# MSS_CPSW register map
Vendor: Texas Instruments
Peripheral module from a debugger description file (folder awr2544).
Registers are 32-bit, read-write, no defined reset value unless marked. A register's access mark holds for its fields unless they carry their own. Offsets are as the file gives them; lines under a group give offsets from that group; [hi:lo] are bit positions; {n}, {i} and the like mark numbered series; 'fields as' and 'values as' point back to an identical list; <NAME> marks a mode.

## MSS_CPSW (part 1 of 3)
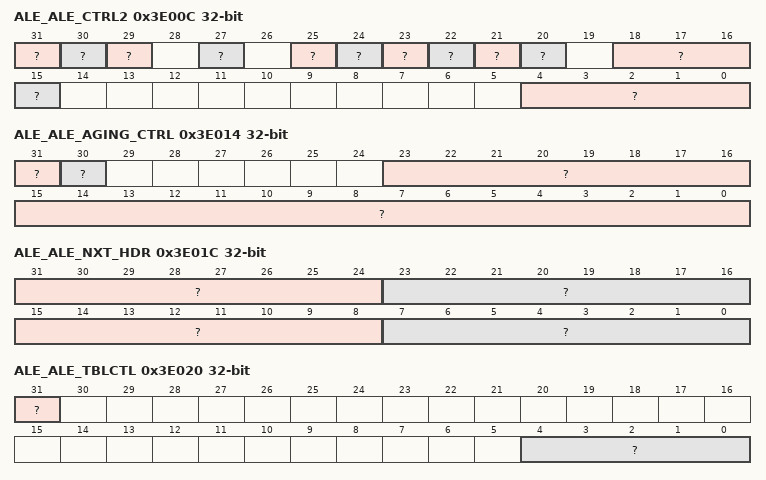
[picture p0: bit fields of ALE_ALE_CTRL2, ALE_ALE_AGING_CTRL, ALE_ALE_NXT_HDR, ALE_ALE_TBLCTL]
0x3E00C ALE_ALE_CTRL2 — The ALE Control 2 Register is used to set the extended features used for all ports.
  [31] ? — Trunk Enable Destination Address - This field enables the destination MAC address to be used with the hash function G(X) = 1 + X + X^3 and affect the trunk port transmit link determination.
  [30] ? — Trunk Enable Source Address - This field enables the source MAC address to be used with the hash function G(X) = 1 + X + X^3 and affect the trunk port transmit link determination.
  [29] ? — Trunk Enable Priority - This field enables the VLAN Priority bits to be used with the hash function G(X) = 1 + X + X^3 and affect the trunk port transmit link determination. In the event that DSCP mapping is enabled and there is no VLAN the DSCP priority will be used. For all other non IP frames without VLAN the port default priority is used.
  [27] ? — Trunk Enable Inner VLAN - This field enables the inner VLAN ID value (C-VLANID) to be used with the hash function G(X) = 1 + X + X^3 and affect the trunk port transmit link determination.
  [25] ? — Trunk Enable Source IP Address - This field enables the source IP address to be used with the hash function G(X) = 1 + X + X^3 and affect the trunk port transmit link determination.#br#This feature supports No tag, Priority tagged, VLAN tagged, Q-in-Q double tagging for both IPV6 and IPV4.
  [24] ? — Trunk Enable Destination IP Address - This field enables the destination IP address to be used with the hash function G(X) = 1 + X + X^3 and affect the trunk port transmit link determination.#br#This feature supports No tag, Priority tagged, VLAN tagged, Q-in-Q double tagging for both IPV6 and IPV4.
  [23] ? — Drop Bad Length will drop any packet that the 802.3 length field is larger than the packet. Ethertypes 0-1500 are 802.3 lengths, all others are Ether types.
  [22] ? — No Drop Source Multicast will disable the dropping of any source address with the multicast bit set.
  [21] ? — Default No Frag field will cause an IPv4 fragmented packet to be dropped if a VLAN entry is not found.
  [20] ? — Default limit next header field will cause an IPv4 protocol or IPv6 next header packet to be dropped if a VLAN entry is not found and the protocol or next header does not match the ~iALE_NXT_HDR register values.
  [18:16] ? — Trunk Base - This field is the hash formula starting value. Changing this value will cause the packet distribution on trunk ports to be changed. If all the ~itrk_en_dst, ~itrk_en_src, ~itrk_en_pri and ~itrk_en_vlan are '0', this value is used as the distribution index. That is a '0' will select the 1st bit of an 'N' link trunk, a '1' will select the second, etc. #br#Below is the distribution across the trunk links. The first number in the ~iitalic sequence indicates the traffic is sent to the lowest numbered port of a trunk group. For example if you have a 3 port trunk, the hash result 0 will go to the base port (0), hash result 1 will go to the highest port of the trunk group (2), hash result 2 will go to the middle port (1), etc.#br# 1 - ~i00000000#br# 2 - ~i01010101#br# 3 - ~i02102102#br# 4 - ~i03210321
  [15] ? — The ~multihost allows host traffic to be sent bact to the host if the DA is market for the host port.
  [4:0] ? — Mirror Index - This field is the ALE lookup table entry index that when a match occurs will cause this traffic to be mirrored to the ~imirror_top port. That is any VLAN, ONU or address with or withou VLAN can be selected for traffic mirroring.
0x3E010 ALE_ALE_PRESCALE — The ALE Prescale Register is used to set the Broadcast and Multicast rate limiting prescaler value.
  [19:0] ? — ALE Prescale - The input clock is divided by this value for use in the multicast/broadcast rate limiters. The minimum operating value is 0x10. The prescaler is off when the value is zero.
0x3E014 ALE_ALE_AGING_CTRL — The ALE Aging Control sets the aging interval which will cause periodic aging to occur. This value specifies the minimum time between aging starts.
  [31] ? — ALE Prescaler 2 Disable - When set will divide the aging interval by 1000. This bit is designed for device verification and should not be used in production software. Combination of PreScale1Disable and PreScale2Disable will divide the aging interval by 1,000,000 for test purposes.
  [30] ? — ALE Prescaler 1 Disable - When set will divide the aging interval by 1000. This bit is designed for device verification and should not be used in production software. Combination of PreScale1Disable and PreScale2Disable will divide the aging interval by 1,000,000 for test purposes.
  [23:0] ? — ALE Aging Timer - This field specifies the number of clock cycles times 1,000,000 between aging operations.
0x3E01C ALE_ALE_NXT_HDR — The ALE Next Header is used to limit the IPv6 Next header or IPv4 Protocol values found in the IP header. It is enabled via the ~iLmtNxtHdr bit in the VLAN entry. All four ~iip_nxt_hdr0-3 are compared when enabled, so if only one is required, set them all to the one value to be tested.
  [31:24] ? — The ~iip_nxt_hdr3 is the forth protocol or next header compared when enabled.
  [23:16] ? — The ~iip_nxt_hdr2 is the third protocol or next header compared when enabled.
  [15:8] ? — The ~iip_nxt_hdr1 is the second protocol or next header compared when enabled.
  [7:0] ? — The ~iip_nxt_hdr0 is the first protocol or next header compared when enabled.
0x3E020 ALE_ALE_TBLCTL — The ALE table control register is used to read or write that ALE table entries. After writing to this register any read or write to any ALE register will be stalled until the read or write operation completes.
  [31] ? — Table Write - This bit is used to write the table words to the lookup table.#br# 0 - Table Read Operation is performed. The contents of the ~b TABLEIDX entry will be read into the ~b ALE_TBLWx registers#br# 1 - Table write operation is performed. This will take the current contents from the ~b ALE_TBLWx registers and write them to the table at the specified ~b TABLEIDX.
  [4:0] ? — The table index is used to determine which lookup table entry is read or written.
0x3E034 ALE_ALE_TBLW2 — The ALE Table Word 2 is the most significant word of an ALE table entry.
  [6:0] ? — Table Entry bits [71:64]
0x3E038 ALE_ALE_TBLW1 — The ALE Table Word 1 is the middle word of an ALE table entry.
  [31:0] ? — Table Entry bits [63:32]
0x3E03C ALE_ALE_TBLW0 — The ALE Table Word 0 is the least significant word of an ALE table entry.
  [31:0] ? — Table Entry bits [31:0]
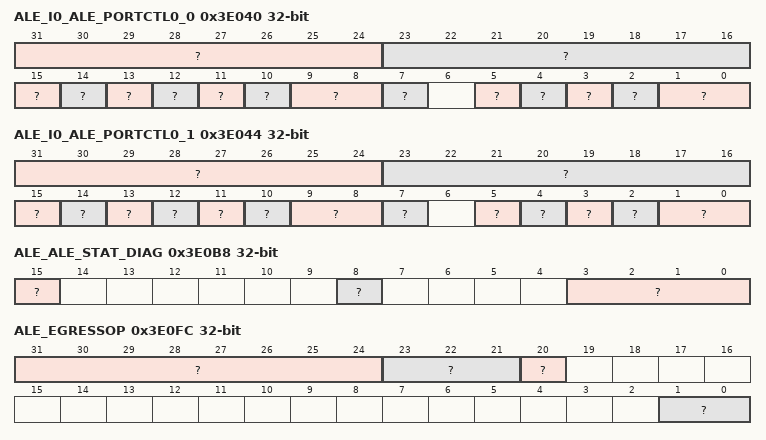
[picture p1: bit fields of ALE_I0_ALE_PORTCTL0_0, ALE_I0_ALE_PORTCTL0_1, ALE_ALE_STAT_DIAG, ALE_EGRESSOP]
0x3E040 ALE_I0_ALE_PORTCTL0_0 — The ALE Port Control Register sets the port specific modes of operation.
  [31:24] ? — Broadcast Packet Rate Limit - Each prescale pulse loads this field into the port broadcast rate limit counter. The port counters are decremented with each packet received or transmitted depending on whether the mode is transmit or receive. If the counters decrement to zero, then further packets are rate limited until the next prescale pulse.#br#Broadcast rate limiting is enabled by a non-zero value in this field.
  [23:16] ? — Multicast Packet Rate Limit - Each prescale pulse loads this field into the port multicast rate limit counter. The port counters are decremented with each packet received or transmitted depending on whether the mode is transmit or receive. If the counters decrement to zero, then further packets are rate limited until the next prescale pulse.#br#Multicast rate limiting is enabled by a non-zero value in this field.The ~imcast_limit is the number of Multicast packets that will be forwaded per ~iale_prescale time.
  [15] ? — Drop Double VLAN - When set cause any received packet with double VLANs to be dropped. That is if there are two ctag or two stag fields in the packet it will be dropped.
  [14] ? — Drop Dual VLAN - When set will cause any received packet with dual VLAN stag followed by ctag to be dropped.
  [13] ? — Mac Only Copy All Frames - When set a Mac Only port will transfer all received good frames to the host. When clear a Mac Only port will transfer packets to the host based on ALE destination address lookup operation (which operates more like an Ethernet Mac).#br#A Mac Only port is a port with ~imaconly set.
  [12] ? — Disable Port authorization - When set will allow unknown addresses to arrive on a switch in authorization mode. It is intended for device to device network connection on ports which do not require MACSEC encryption.
  [11] ? — MAC Only - When set enables this port be treated like a MAC port for the host. All traffic received is only sent to the host. The host must direct traffic to this port as the lookup engine will not send traffic to the ports with the ~ip0_maconly bit set and the ~ip0_no_learn also set. If ~ip0_maconly bit is set and the ~ip0_no_learn is not set, the host can send non-directed packets that can be sent to the destination of a MacOnly port. It is also possible that The host can broadcast to all ports including MacOnly ports in this mode.
  [10] ? — Trunk Enable - This field is used to enable a port into a trunk. Any port can be used as a trunk port, any two or more ports with the ~ip0_trunken its set and having the same ~ip0_trunknum will be placed in the same trunk. There is no requirement for trunk ports to be adjacent. If all ports are enabled in the same trunk, no traffic can flow as traffic received within a trunk is never trasnmitted out the same trunk. If only a single port is a member of a trunk, it looks like a normal port with exception of entries in the look up table will be noted as a trunk entry.
  [9:8] ? — Trunk Number - This field is used as the trunk number when the ~ip0_trunken is also set. Ports with the same trunk number that have the ~ip0_trunken also set will have traffic distributed within the trunk based on the result of the hash function descrived above.
  [7] ? — Mirror Source Port - This field enables the source port mirror option. When this bit is set any traffic received on the port with the reg_p0_mirror_sp bit set will have its received traffic also sent to the ~imirror_top port.
  [5] ? — No Source Address Update - When set will not update the source addresses for this port.
  [4] ? — No Learn - When set will not learn the source addresses for this port.
  [3] ? — VLAN Ingress Check - When set if a packet received is not a member of the VLAN, the packet will be dropped.
  [2] ? — If Drop Untagged - When set will drop packets without a VLAN tag.
  [1:0] ? — Port State - Defins the current port state used for lookup operations.#br# 0 - Disabled#br# 1 - Blocked#br# 2 - Learning#br# 3 - Forwarding
0x3E044 ALE_I0_ALE_PORTCTL0_1 — The ALE Port Control Register sets the port specific modes of operation.
  fields as ALE_I0_ALE_PORTCTL0_0
0x3E090 ALE_ALE_UVLAN_MEMBER — The ALE Unknown VLAN Member Mask Register is used to specify the member list for unknown VLAN ID.
  [1:0] ? — Unknown VLAN Member List - Each bit represents the port member status for unknown VLANs.
0x3E094 ALE_ALE_UVLAN_URCAST — The ALE Unknown VLAN Unregistered Multicast Flood Mask Register is used to specify which egress ports unregistered multicast addresses egress for the unregistered VLAN ID.
  [1:0] ? — Unknown VLAN Unregister Multicast Flood Mask - Each bit represents the port to which unregistered multicast are sent for unregistered VLANs.
0x3E098 ALE_ALE_UVLAN_RMCAST — The ALE Unknown VLAN Registered Multicast Flood Mask Register is used to specify which egress ports registered multicast addresses egress for the unregistered VLAN ID.
  [1:0] ? — Unknown VLAN Register Multicast Flood Mask - Each bit represents the port to which registered multicast are sent for unregistered VLANs. This field is ANDed with the registered multicast mask to determine the destinations for unregistered VLANs.
0x3E09C ALE_ALE_UVLAN_UNTAG — The ALE Unknown VLAN force Untagged Egress Mask Register is used to specify which egress ports the VLAN ID will be removed.
  [1:0] ? — Unknown VLAN Force Untagged Egress Mask - Each bit represents the port where the VLAN will be removed for unregistered VLANs.
0x3E0B4 ALE_ALE_FAST_LUT — The Fast LUT registers allows the ports to be placed in Fast LUT mode.
  [1:0] ? — The ~Fast_LUT field alows any port to be Fast_LUT mode, which will cause all lookup operations to start based on DA/SA and VLAN only. That is any data beyong the first 32 are not used in the lookup process.
0x3E0B8 ALE_ALE_STAT_DIAG — The ALE Statistic Output Diagnostic Register allows the output statistics to diagnose the SW counters. This register is for diagnostice only.
  [15] ? — When set and the ~iport_diag is set to zero, will allow all ports to see the same stat diagnostic increment.
  [8] ? — The port selected that a received packet will cause the selected error to increment
  [3:0] ? — When non-zero will cause the selected statistic to increment on the next frame received. For the selected Port. #br# 0: Disabled#br# 1: Destination Equal Source Drop Stat will count#br# 2: VLAN Ingress Check Drop Stat will count#br# 3: Source Multicast Drop Stat will count#br# 4: Dual VLAN Drop Stat will count#br# 5: Ether Type length error Drop Stat will count#br# 6: Next Hop Limit Drop Stat will count#br# 7: IPv4 Fragment Drop Stat will count#br# 8: Classifier Hit Stat will count#br# 9: Classifier Red Drop Stat will count#br# 10: Classifier Yellow Drop Stat will count#br# 11: ALE Overflow Drop Stat will count#br# 12: Rate Limit Drop Stat will count#br# 13: Blocked Address Drop Stat will count#br# 14: Secure Address Drop Stat will count#br# 15: Authorization Drop Stat will count.
0x3E0BC ALE_ALE_OAM_LB_CTRL — The ALE OAM Control allows ports to be put into OAM Loopback, only non-supervisor packet are looped back to the source port.
  [1:0] ? — The ~ioam_lb_ctrl allows any port to be put into OAM loopback, that is any packet received will be returned to the same port with an egressop of 0xFF which swaps the source and destination address. BPDUs will still flow through as normal so that OAM can be remotly requested and disabled.
0x3E0C0 ALE_ALE_MSK_MUX0 ro — VLAN Mask Mux x - The ALE Mask Mux registers are used along with the VLAN registered/unregistered index selectors from the Lookup Table to determine the value for vlan registered and unregister mask respectively.
  [1:0] ? — VLAN Mask Mux x - When selected by the VLAN lookup table entry FwdUnRegIdx or FwdAllRegIdx is used as the FwdUnRegMask or FwdUnRegMask values anded with the member list to determine the forwarding of packets. The Value of vlan_mask_mux_0 is read only and set to all ones for all ports.
{0x3E0C4+4i} ALE_I1_ALE_MSK_MUX1_{i} (i=0..2) — VLAN Mask Mux x - The ALE Mask Mux registers are used along with the VLAN registered/unregistered index selectors from the Lookup Table to determine the value for vlan registered and unregister mask respectively.
  fields as ALE_ALE_MSK_MUX0
0x3E0FC ALE_EGRESSOP — The Egress Operation register allows enabled classifiers with any match like IPSA or IPDA match to use the CPSW Egress Packet Operations Inter VLAN Routing sub functions. If the packet was destined for the host or is destined to any port without any errors, but matches a clasifier that has a programmed egress opcode, it will be forwarded to the destination ports where the destination ports will use the thier egress opcode entry to modify the packet. InterVLAN Routing and mirroring need to be understood, they are orthogonal functions. Care must be taken not to violate VLAN rules as this can redirect packets based on classifier matches.
  [31:24] ? — The Egress Operation defines the operation performed by the CPSW Egress Packet Operations#br# 0: NOP#br#: 1-n: Defines which egress Operation will be performed. This allows Inter VLAN routing to be configured for high bandwidth traffic, reducing CPU load.#br# 0xff: Swap SA and DA of packet, this is intended to allow OAM diagnostics for a link.
  [23:21] ? — The Egress Trunk Index is the calculated trunk index from the SA, DA or VLAN if modified to that InterVLAN routing will work on trunks as well. The DA, SA and VLAN are ignored for trunk generation on InterVLAN Routing so that this field is the index generated from the Egress Op replacements elclusive or'd together into a three bit index.
  [20] ? — The TTL Check will cause any packet that fails TTL checks to not be routed to the Inter VLAN Routing sub functions. The packet will be routed to the host it was destined to.
  [1:0] ? — The Destination Ports is a list of the ports the classified packet will be set to. If a destination is a Trunk, all the port bits for that trunck must be set.
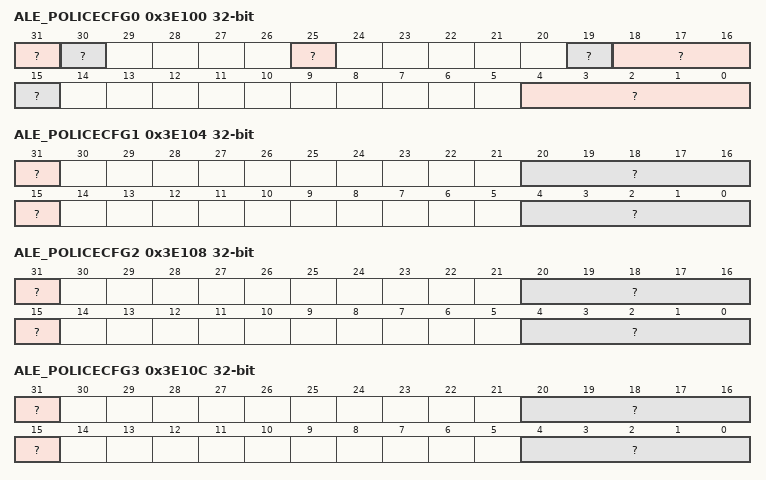
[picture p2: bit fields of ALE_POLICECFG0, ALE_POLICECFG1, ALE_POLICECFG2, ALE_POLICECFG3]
0x3E100 ALE_POLICECFG0 — The Policing Config 0 holds the port, frame priority and ONU address index as well as match enables for port, frame priority and ONU address matching.
  [31] ? — Port Match Enable - Enabled port match for the selected policing/classifier entry
  [30] ? — Trunk ID - When set indicates the port number is a trunk group.
  [25] ? — Port Number - Specifies the port address to match for the selected policing/classifier entry
  [19] ? — Priority Match Enable - Enables frame priority match for the selected policing/classifier entry
  [18:16] ? — Priority Value - Specifies the frame priority to match for the selected policing/classifier entry
  [15] ? — OUI Match Enable - Enables frame ONU address match for the selected policing/classifier entry
  [4:0] ? — OUI Table Entry Index - Specifies the ALE ONU address lookup table index to match for the selected policing/classifier entry
0x3E104 ALE_POLICECFG1 — The Policing Config 1 holds the match enable/match index for the L2 Destination and L2 source addresses
  [31] ? — Destination Address Match Enable - Enables frame L2 destination address match for the selected policing/classifier entry
  [20:16] ? — Destination Address Table Entry Index - Specifies the ALE L2 destination address lookup table index to match for the selected policing/classifier entry
  [15] ? — Source Address Match Enable - Enables frame L2 source address match for the selected policing/classifier entry
  [4:0] ? — Source Address Table Entry Index - Specifies the ALE L2 source address lookup table index to match for the selected policing/classifier entry
0x3E108 ALE_POLICECFG2 — The Policing Config 2 holds the match enable/match index for the Outer VLAN and Inner VLAN addresses
  [31] ? — Outer VLAN Match Enable - Enables frame Outer VLAN address match for the selected policing/classifier entry
  [20:16] ? — Outer VLAN Table Entry Index - Specifies the ALE Outer VLAN address lookup table index to match for the selected policing/classifier entry#br# Note this index assumes the VLANID is in the packet, it does not use the port VLAN if the packet in untagged or priority tagged.
  [15] ? — Inner VLAN Match Enable - Enables frame Inner VLAN address match for the selected policing/classifier entry
  [4:0] ? — Inner VLAN Table Entry Index - Specifies the ALE Inner VLAN address lookup table index to match for the selected policing/classifier entry#br# Note this index assumes the VLANID is in the packet, it does not use the port VLAN if the packet in untagged or priority tagged.
0x3E10C ALE_POLICECFG3 — The Policing Config 3 holds the match enable/match index for the Ether Type and IP Source address
  [31] ? — EtherType Match Enable - Enables frame Ether Type match for the selected policing/classifier entry
  [20:16] ? — EtherType Table Entry Index - Specifies the ALE Ether Type lookup table index to match for the selected policing/classifier entry
  [15] ? — IP Source Address Match Enable - Enables frame IP Source address match for the selected policing/classifier entry
  [4:0] ? — IP Source Address Table Entry Index - Specifies the ALE IP Source address lookup table index to match for the selected policing/classifier entry
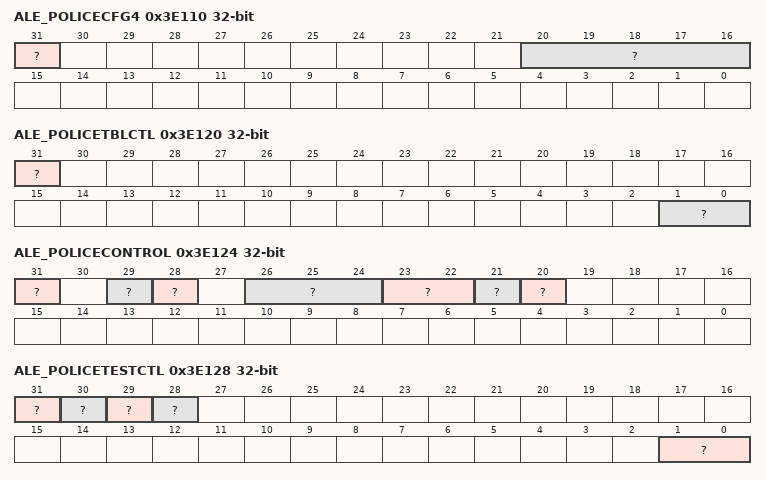
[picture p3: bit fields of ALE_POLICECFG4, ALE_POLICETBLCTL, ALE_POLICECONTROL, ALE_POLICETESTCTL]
0x3E110 ALE_POLICECFG4 — The Policing Config 4 holds the match enable/match index for the IP Destination address
  [31] ? — IP Destination Address Match Enable - Enables frame IP Destination address match for the selected policing/classifier entry
  [20:16] ? — IP Destination Address Table Entry Index - Specifies the ALE IP Destination address lookup table index to match for the selected policing/classifier entry
0x3E118 ALE_POLICECFG6 — The PIR counter is a 37 bit internal counter where ~ipir_idle_inc_val is added every clock and the frame size << 18 is subtracted at EOF if not RED at LUT time. If the counter is negative the packet will be marked RED, else it can be YELLOW or GREEN based on the CIR counter. If only this counter is used (aka cir_idle_inc_val==0) Packet are marked RED or GREEN based on PIR counter only.
  [31:0] ? — Peak Information Rate Idle Increment Value - The number added to the PIR counter every clock cycle. If zero the PIR counter is disabled and packets will never be marked or processed as RED.
0x3E11C ALE_POLICECFG7 — The CIR counter is a 37 bit internal counter where ~icir_idle_inc_val is added every clock and the frame size << 18 is subtracted at EOF if not RED or YELLOW at LUT time. If the counter is positive the packet will be marked GREEN, else it can be YELLOW or RED based on the PIR counter. If only this counter is used (aka pir_idle_inc_val==0) Packet are marked YELLOW or GREEN based on CIR counter only.
  [31:0] ? — Committed Information Idle Increment Value - The number added to the CIR counter every clock cycle. If zero the CIR counter is disabled and packets will never be marked or processed as YELLOW.
0x3E120 ALE_POLICETBLCTL — The Policing Table Control is used to read or write the selected policing/classifier entry. The selected policing/classifier entry is only read or written after this register is written based on the value of the ~iwrite_enable bit.
  [31] ? — Write Enable - Setting this bit will write the POLICECFG0-7 to the ~ipol_tbl_idx selected policing/classifier entry. Clearing this bit will read the ~ipol_tbl_idx selected policing/classifier entry into the POLICECFG0-7 registers.
  [1:0] ? — Policer Entry Index - This field specifies the policing/classifier entry to be read or written. When writing to this field without setting the ~iwrite_enable=1 will cause the selected policing/classifier entry to be loaded into the POLICECFG0-7 registers. When writing to this field with setting the ~iwrite_enable=1 will cause the selected policing/classifier entry to be updated from the POLICECFG0-7 registers.
0x3E124 ALE_POLICECONTROL — The Control Enables color marking as well as internal ALE packet dropping rules.
  [31] ? — Policing Enable - Enables the policing to color the packets, this also enables red or yellow drop capabilities.
  [29] ? — RED Drop Enable - Enables the ALE to drop the red colored packets.
  [28] ? — WELLOW Drop Enable - Enables the ALE to drop yellow packets based on the ~iyellowthresh value. This field would normally not be used as to let the switch drop packets at a buffer threshold instead. In the event that the switch does not enable buffer threshold dropping, YELLOW packets can be dropped based on this feature.
  [26:24] ? — Yellow Threshold - When set enables a portion of the yellow packets to be dropped based on the ~iyellow_drop_en enable.#br# 0-100%#br# 1=50%#br# 2-33%#br# 3-25%#br# 4=20%#br# 5-17%#br# 6-14%#br# 7-13%
  [23:22] ? — Policing Match Mode - This field determines what happens to packets that fail to hit any policing/classifier entry.#br# 0 - No Hit packets are marked GREEN#br# 1 - No Hit packets are marked YELLOW#br# 2 - No Hit packets are marked RED#br# 3 - No Hit packets are marked based on policing/classifier entry=0 state.
  [21] ? — Priority Thread Enable - This field determines if priority is OR'd to the default thread when no classifiers hit and the default thread is enabled.
  [20] ? — MAC Only Default Disable - This field when set disables the default thread on MAC Only Ports. That is the default thread will be {port,priority}. If the traffic matches a classifier with a thread mapping, the classifier thread mapping still occurs.
0x3E128 ALE_POLICETESTCTL — The Policing Test Control enables the ability to determine which policing entry has been hit and whether they reported a red or yellow rate condition.
  [31] ? — Policer Clear - This bit clears all the policing/classifier hit bits. This bit is self clearing. This can be used to test the fact that a policing/classifier entry has been hit.
  [30] ? — Policer Clear RED - This bit clears all the policing/classifier RED hit bits. This bit is self clearing. This can be used to test the fact that a policing/classifier entry has been hit during a RED condition.
  [29] ? — Policer Clear YELLOW - This bit clears all the policing/classifier YELLOW hit bits. This bit is self clearing. This can be used to test the fact that a policing/classifier entry has been hit during a YELLOW condition.
  [28] ? — Police Clear Selected - This bit clears the selected policing/classifier hit, redhit and yellowhit bits. This bit is self clearing.
  [1:0] ? — Policer Test Index - This field selects which policing/classifier hit bits will be read or written.
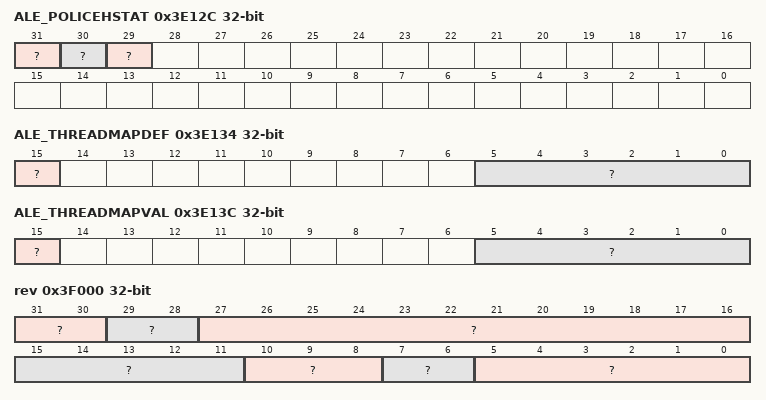
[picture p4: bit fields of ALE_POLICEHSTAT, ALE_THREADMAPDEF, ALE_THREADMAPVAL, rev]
0x3E12C ALE_POLICEHSTAT ro — The policing hit status is a read only register that reads the hit bits of the selected policing/classifier.
  [31] ? — Policer Hit - This indicates that the selected policing/classifier via the ~ipol_test_idx field has been hit by a packet seen on any port that matches the policing/classifier entry match.
  [30] ? — Policer Hit RED - This indicates that the selected policing/classifier via the ~ipol_test_idx field has been hit during a RED condition by a packet seen on any port that matches the policing/classifier entry match.
  [29] ? — Policer Hit YELLOW - This indicates that the selected policing/classifier via the ~ipol_test_idx field has been hit during a YELLOW condition by a packet seen on any port that matches the policing/classifier entry match.
0x3E134 ALE_THREADMAPDEF — The THREAD Mapping Default Value register is used to set the default thread ID when no classifier is matched,
  [15] ? — Default Tread Enable - When set the switch will use the ~idefthreadval for the host interface thread ID if no classifier is matched. If clear the switch will generate its own thread ID based on port and priority if there is no classifier match.
  [5:0] ? — Default Thread Value - This field specifies the default thread ID value.
0x3E138 ALE_THREADMAPCTL — The THREAD Mapping Control register allows the highest matched classifier to return a particular thread ID for traffic sent to the host. This allows particular classifier matched traffic to be placed an a particular hosts queue.
  [1:0] ? — Classifier Index - This is the classifier index entry that the thread enable and thread value will be read or written by the ~bTHREADMAPVAL register.
0x3E13C ALE_THREADMAPVAL — The THREAD Mapping Value register is used to set the thread ID for a particular classifier entry.
  [15] ? — Thread Enable - When set the switch will use the ~ithreadval for the selected classifier match. If clear the the thread ID will be determined by the ~bTHREADMAPDEF register settings.
  [5:0] ? — Thread Value - This field is the thread ID value that is used to map a classifier hit to thread ID for host traffic.
0x3F000 rev ro — Revision parameters
  [31:30] ? — Scheme
  [29:28] ? — bu
  [27:16] ? — Module ID
  [15:11] ? — RTL version
  [10:8] ? — Major version
  [7:6] ? — Custom version
  [5:0] ? — Minor version
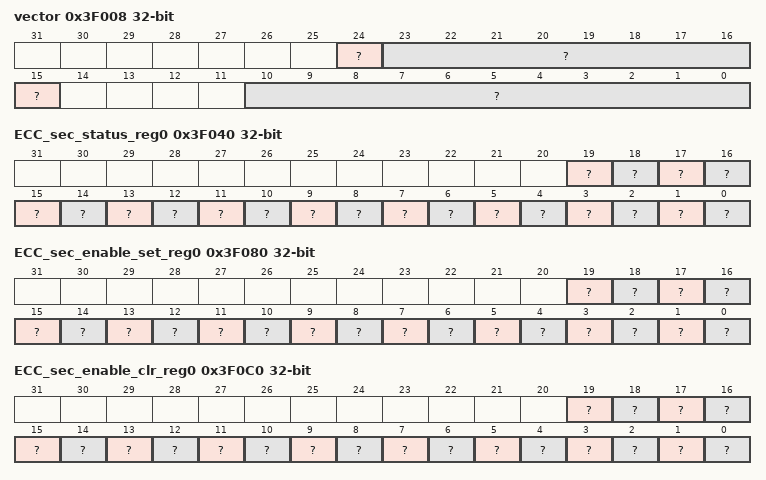
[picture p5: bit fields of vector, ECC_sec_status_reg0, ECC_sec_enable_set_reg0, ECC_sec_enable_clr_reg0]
0x3F008 vector — ECC Vector Register
  [24] ? — Status to indicate if read on serial VBUS is complete, write of any value will clear this bit.
  [23:16] ? — Read address
  [15] ? — Write 1 to trigger a read on the serial VBUS
  [10:0] ? — Value written to select the corresponding ECC RAM for control or status
0x3F00C stat ro — Misc Status
  [10:0] ? — Indicates the number of RAMS serviced by the ECC aggregator
{0x3F010+4i} ECC_reserved_svbus_{i} (i=0..7) — Reference other documents that contain the ECC RAM wrapper and EDC controller serial vbus register sets.
  [31:0] ? — Serial VBUS register data
0x3F03C ECC_sec_eoi_reg — EOI Register
  [0] ?
0x3F040 ECC_sec_status_reg0 — Interrupt Status Register 0
  [19] ? — Interrupt Pending Status for ramecc19_pend
  [18] ? — Interrupt Pending Status for ramecc18_pend
  [17] ? — Interrupt Pending Status for ramecc17_pend
  [16] ? — Interrupt Pending Status for ramecc16_pend
  [15] ? — Interrupt Pending Status for ramecc15_pend
  [14] ? — Interrupt Pending Status for ramecc14_pend
  [13] ? — Interrupt Pending Status for ramecc13_pend
  [12] ? — Interrupt Pending Status for ramecc12_pend
  [11] ? — Interrupt Pending Status for ramecc11_pend
  [10] ? — Interrupt Pending Status for ramecc10_pend
  [9] ? — Interrupt Pending Status for ramecc9_pend
  [8] ? — Interrupt Pending Status for ramecc8_pend
  [7] ? — Interrupt Pending Status for ramecc7_pend
  [6] ? — Interrupt Pending Status for ramecc6_pend
  [5] ? — Interrupt Pending Status for ramecc5_pend
  [4] ? — Interrupt Pending Status for ramecc4_pend
  [3] ? — Interrupt Pending Status for ramecc3_pend
  [2] ? — Interrupt Pending Status for ramecc2_pend
  [1] ? — Interrupt Pending Status for ramecc1_pend
  [0] ? — Interrupt Pending Status for ramecc0_pend
0x3F080 ECC_sec_enable_set_reg0 — Interrupt Enable Set Register 0
  [19] ? — Interrupt Enable Set Register for ramecc19_pend
  [18] ? — Interrupt Enable Set Register for ramecc18_pend
  [17] ? — Interrupt Enable Set Register for ramecc17_pend
  [16] ? — Interrupt Enable Set Register for ramecc16_pend
  [15] ? — Interrupt Enable Set Register for ramecc15_pend
  [14] ? — Interrupt Enable Set Register for ramecc14_pend
  [13] ? — Interrupt Enable Set Register for ramecc13_pend
  [12] ? — Interrupt Enable Set Register for ramecc12_pend
  [11] ? — Interrupt Enable Set Register for ramecc11_pend
  [10] ? — Interrupt Enable Set Register for ramecc10_pend
  [9] ? — Interrupt Enable Set Register for ramecc9_pend
  [8] ? — Interrupt Enable Set Register for ramecc8_pend
  [7] ? — Interrupt Enable Set Register for ramecc7_pend
  [6] ? — Interrupt Enable Set Register for ramecc6_pend
  [5] ? — Interrupt Enable Set Register for ramecc5_pend
  [4] ? — Interrupt Enable Set Register for ramecc4_pend
  [3] ? — Interrupt Enable Set Register for ramecc3_pend
  [2] ? — Interrupt Enable Set Register for ramecc2_pend
  [1] ? — Interrupt Enable Set Register for ramecc1_pend
  [0] ? — Interrupt Enable Set Register for ramecc0_pend
0x3F0C0 ECC_sec_enable_clr_reg0 — Interrupt Enable Clear Register 0
  [19] ? — Interrupt Enable Clear Register for ramecc19_pend
  [18] ? — Interrupt Enable Clear Register for ramecc18_pend
  [17] ? — Interrupt Enable Clear Register for ramecc17_pend
  [16] ? — Interrupt Enable Clear Register for ramecc16_pend
  [15] ? — Interrupt Enable Clear Register for ramecc15_pend
  [14] ? — Interrupt Enable Clear Register for ramecc14_pend
  [13] ? — Interrupt Enable Clear Register for ramecc13_pend
  [12] ? — Interrupt Enable Clear Register for ramecc12_pend
  [11] ? — Interrupt Enable Clear Register for ramecc11_pend
  [10] ? — Interrupt Enable Clear Register for ramecc10_pend
  [9] ? — Interrupt Enable Clear Register for ramecc9_pend
  [8] ? — Interrupt Enable Clear Register for ramecc8_pend
  [7] ? — Interrupt Enable Clear Register for ramecc7_pend
  [6] ? — Interrupt Enable Clear Register for ramecc6_pend
  [5] ? — Interrupt Enable Clear Register for ramecc5_pend
  [4] ? — Interrupt Enable Clear Register for ramecc4_pend
  [3] ? — Interrupt Enable Clear Register for ramecc3_pend
  [2] ? — Interrupt Enable Clear Register for ramecc2_pend
  [1] ? — Interrupt Enable Clear Register for ramecc1_pend
  [0] ? — Interrupt Enable Clear Register for ramecc0_pend
0x3F13C ECC_ded_eoi_reg — EOI Register
  [0] ?
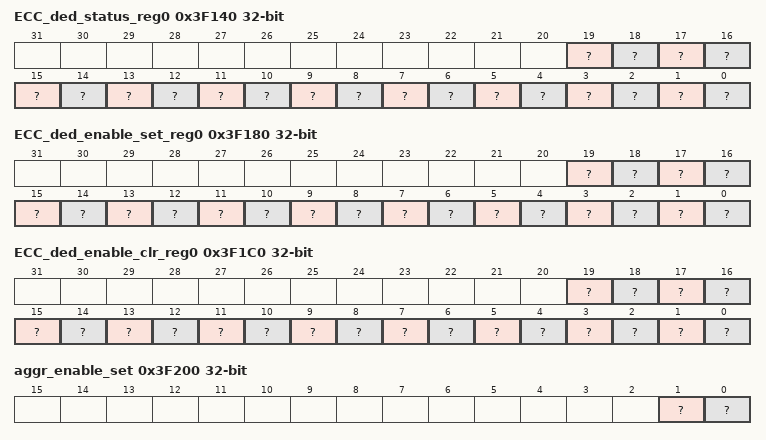
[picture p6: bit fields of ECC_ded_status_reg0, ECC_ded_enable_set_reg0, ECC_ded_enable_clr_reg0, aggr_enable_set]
0x3F140 ECC_ded_status_reg0 — Interrupt Status Register 0
  fields as ECC_sec_status_reg0
0x3F180 ECC_ded_enable_set_reg0 — Interrupt Enable Set Register 0
  fields as ECC_sec_enable_set_reg0
0x3F1C0 ECC_ded_enable_clr_reg0 — Interrupt Enable Clear Register 0
  fields as ECC_sec_enable_clr_reg0
0x3F200 aggr_enable_set — AGGR interrupt enable set Register
  [1] ? — interrupt enable set for svbus timeout errors
  [0] ? — interrupt enable set for parity errors
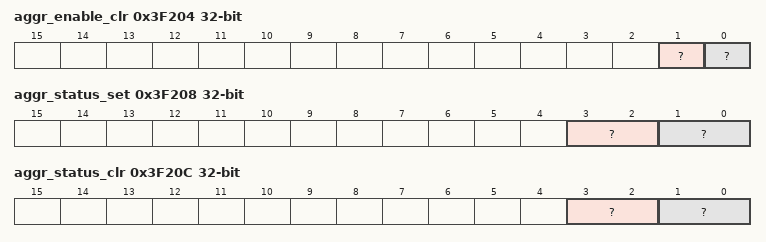
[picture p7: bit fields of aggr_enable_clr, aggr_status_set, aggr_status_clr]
0x3F204 aggr_enable_clr — AGGR interrupt enable clear Register
  [1] ? — interrupt enable clear for svbus timeout errors
  [0] ? — interrupt enable clear for parity errors
0x3F208 aggr_status_set — AGGR interrupt status set Register
  [3:2] ? — interrupt status set for svbus timeout errors
  [1:0] ? — interrupt status set for parity errors
0x3F20C aggr_status_clr — AGGR interrupt status clear Register
  [3:2] ? — interrupt status clear for svbus timeout errors
  [1:0] ? — interrupt status clear for parity errors
